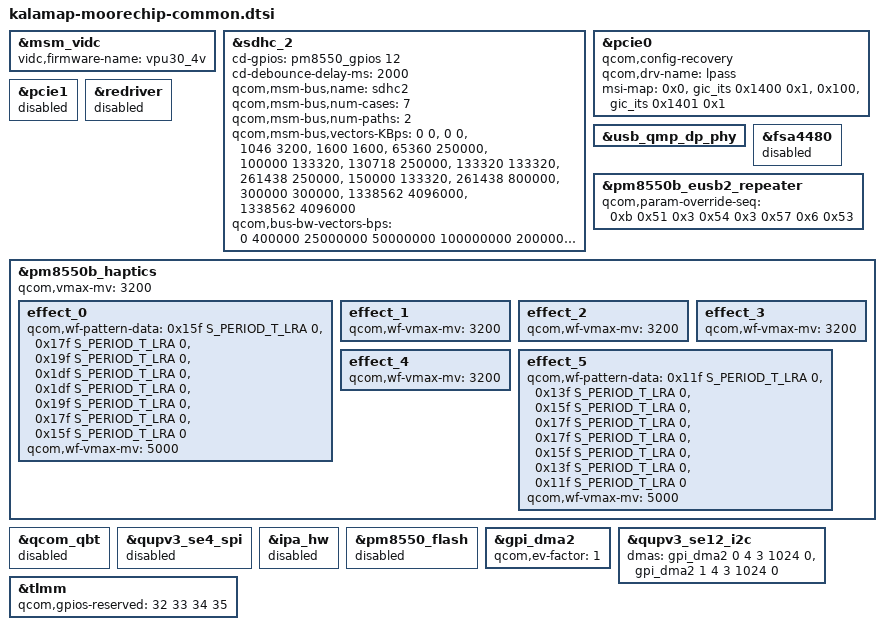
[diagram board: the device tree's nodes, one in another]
#include "../qcom/kalama-qrd.dtsi"

#include "kalamap-moorechip-joystick.dtsi"
#include "kalamap-moorechip-thermal.dtsi"
#include "kalamap-moorechip-rpmh.dtsi"

&msm_vidc {
	vidc,firmware-name = "vpu30_4v";
};

&sdhc_2 {
	cd-gpios = <&pm8550_gpios 12 GPIO_ACTIVE_HIGH>;
	cd-debounce-delay-ms = <2000>;

	qcom,msm-bus,name = "sdhc2";
	qcom,msm-bus,num-cases = <7>;
	qcom,msm-bus,num-paths = <2>;
	qcom,msm-bus,vectors-KBps =
		/* No Vote */
		<0 0>, <0 0>,
		/* 400 KB/s*/
		<1046 3200>, <1600 1600>,
		/* 25 MB/s */
		<65360 250000>, <100000 133320>,
		/* 50 MB/s */
		<130718 250000>, <133320 133320>,
		/* 100 MB/s */
		<261438 250000>, <150000 133320>,
		/* 200 MB/s */
		<261438 800000>, <300000 300000>,
		/* Max. bandwidth */
		<1338562 4096000>, <1338562 4096000>;
	qcom,bus-bw-vectors-bps = <0 400000 25000000 50000000
		100000000 200000000 4294967295>;
};

&pcie0 {
	qcom,config-recovery;
	qcom,drv-name = "lpass";
	msi-map = <0x0 &gic_its 0x1400 0x1>,
		  <0x100 &gic_its 0x1401 0x1>; /* 32 event IDs */
};

&pcie1 {
	status = "disabled";
};

&usb_qmp_dp_phy {
	pinctrl-names = "default";
};

&redriver {
	status = "disabled";
};

&fsa4480 {
	status = "disabled";
};

&pm8550b_eusb2_repeater {
	qcom,param-override-seq =
		/* <value reg_offset> */
		/* Adjust HS trasmit amplitude */
		<0xb 0x51
		/* Squelch detection threshold */
		 0x3 0x54
		/* Tx pre-emphasis tuning */
		 0x3 0x57
		/* HS disconnect threshold */
		 0x6 0x53>;
};

&pm8550b_haptics {
	status = "okay";
	qcom,vmax-mv = <3200>;

	effect_0 {
		/* CLICK */
		qcom,wf-pattern-data =  <0x15f  S_PERIOD_T_LRA  0>,
					<0x17f  S_PERIOD_T_LRA  0>,
					<0x19f  S_PERIOD_T_LRA  0>,
					<0x1df  S_PERIOD_T_LRA  0>,
					<0x1df  S_PERIOD_T_LRA  0>,
					<0x19f  S_PERIOD_T_LRA  0>,
					<0x17f  S_PERIOD_T_LRA  0>,
					<0x15f  S_PERIOD_T_LRA  0>;
		/delete-property/ qcom,wf-pattern-preload;
		qcom,wf-vmax-mv = <5000>;
	};

	effect_1 {
		/* DOUBLE_CLICK */
		qcom,wf-vmax-mv = <3200>;
	};

	effect_2 {
		/* TICK */
		qcom,wf-vmax-mv = <3200>;
	};

	effect_3 {
		/* THUD */
		qcom,wf-vmax-mv = <3200>;
	};

	effect_4 {
		/* POP */
		qcom,wf-vmax-mv = <3200>;
	};

	effect_5 {
		/* HEAVY CLICK */
		qcom,wf-pattern-data =  <0x11f  S_PERIOD_T_LRA  0>,
					<0x13f  S_PERIOD_T_LRA  0>,
					<0x15f  S_PERIOD_T_LRA  0>,
					<0x17f  S_PERIOD_T_LRA  0>,
					<0x17f  S_PERIOD_T_LRA  0>,
					<0x15f  S_PERIOD_T_LRA  0>,
					<0x13f  S_PERIOD_T_LRA  0>,
					<0x11f  S_PERIOD_T_LRA  0>;
		qcom,wf-vmax-mv = <5000>;
	};
};

&qcom_qbt {
	status = "disabled";
};

&qupv3_se4_spi {
	status = "disabled";
};

&ipa_hw {
	status = "disabled";
};

&pm8550_flash {
	status = "disabled";
};

&gpi_dma2 {
	qcom,ev-factor = <1>;
};

&qupv3_se12_i2c {
	dmas = <&gpi_dma2 0 4 3 1024 0>,
		<&gpi_dma2 1 4 3 1024 0>;
};

&tlmm {
	qcom,gpios-reserved = <32 33 34 35>;
};
